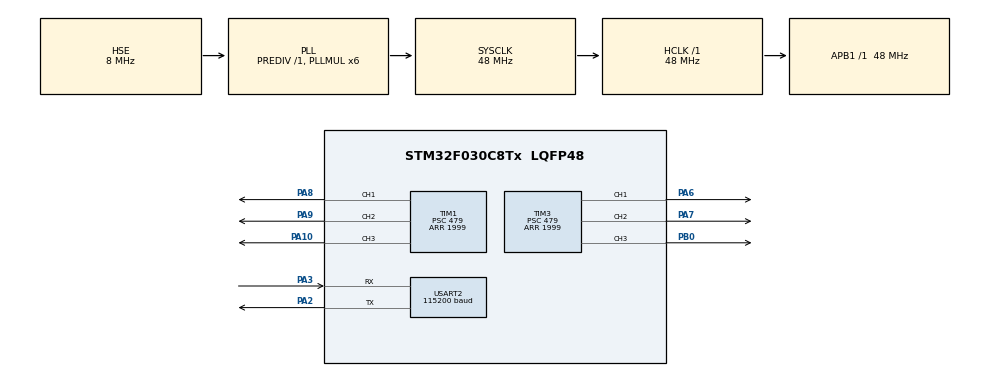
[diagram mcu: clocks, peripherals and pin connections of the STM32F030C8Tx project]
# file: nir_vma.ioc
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Dma.Request0=USART2_RX
Dma.Request1=USART2_TX
Dma.USART2_RX.0.Direction=DMA_PERIPH_TO_MEMORY
Dma.USART2_RX.0.Instance=DMA1_Channel5
Dma.USART2_RX.0.MemDataAlignment=DMA_MDATAALIGN_BYTE
Dma.USART2_RX.0.MemInc=DMA_MINC_ENABLE
Dma.USART2_RX.0.Mode=DMA_CIRCULAR
Dma.USART2_RX.0.PeriphDataAlignment=DMA_PDATAALIGN_BYTE
Dma.USART2_RX.0.PeriphInc=DMA_PINC_DISABLE
Dma.USART2_RX.0.Priority=DMA_PRIORITY_LOW
Dma.USART2_TX.1.Direction=DMA_MEMORY_TO_PERIPH
Dma.USART2_TX.1.Instance=DMA1_Channel4
Dma.USART2_TX.1.MemDataAlignment=DMA_MDATAALIGN_BYTE
Dma.USART2_TX.1.MemInc=DMA_MINC_ENABLE
Dma.USART2_TX.1.Mode=DMA_NORMAL
Dma.USART2_TX.1.PeriphDataAlignment=DMA_PDATAALIGN_BYTE
Dma.USART2_TX.1.PeriphInc=DMA_PINC_DISABLE
Dma.USART2_TX.1.Priority=DMA_PRIORITY_LOW
Mcu.Family=STM32F0
Mcu.Name=STM32F030C8Tx
Mcu.Package=LQFP48
NVIC.DMA1_Channel4_5_IRQn=true\:0\:0\:false\:false\:true\:false\:true\:true
NVIC.USART2_IRQn=true\:0\:0\:false\:false\:true\:true\:true\:true
PA10.Signal=S_TIM1_CH3
PA13.Mode=Serial_Wire
PA13.Signal=SYS_SWDIO
PA14.Mode=Serial_Wire
PA14.Signal=SYS_SWCLK
PA2.Mode=Asynchronous
PA2.Signal=USART2_TX
PA3.Mode=Asynchronous
PA3.Signal=USART2_RX
PA6.Signal=S_TIM3_CH1
PA7.Signal=S_TIM3_CH2
PA8.Signal=S_TIM1_CH1
PA9.Signal=S_TIM1_CH2
PB0.Signal=S_TIM3_CH3
PF0-OSC_IN.Mode=HSE-External-Oscillator
PF0-OSC_IN.Signal=RCC_OSC_IN
PF1-OSC_OUT.Mode=HSE-External-Oscillator
PF1-OSC_OUT.Signal=RCC_OSC_OUT
ProjectManager.HeapSize=0x200
ProjectManager.StackSize=0x400
ProjectManager.TargetToolchain=STM32CubeIDE
RCC.AHBFreq_Value=48000000
RCC.APB1Freq_Value=48000000
RCC.APB1TimFreq_Value=48000000
RCC.HCLKFreq_Value=48000000
RCC.PLLMUL=RCC_PLL_MUL6
RCC.PLLSourceVirtual=RCC_PLLSOURCE_HSE
RCC.SYSCLKFreq_VALUE=48000000
RCC.SYSCLKSource=RCC_SYSCLKSOURCE_PLLCLK
SH.S_TIM1_CH1.0=TIM1_CH1,PWM Generation1 CH1
SH.S_TIM1_CH2.0=TIM1_CH2,PWM Generation2 CH2
SH.S_TIM1_CH3.0=TIM1_CH3,PWM Generation3 CH3
SH.S_TIM3_CH1.0=TIM3_CH1,PWM Generation1 CH1
SH.S_TIM3_CH2.0=TIM3_CH2,PWM Generation2 CH2
SH.S_TIM3_CH3.0=TIM3_CH3,PWM Generation3 CH3
TIM1.Channel-PWM\ Generation1\ CH1=TIM_CHANNEL_1
TIM1.Channel-PWM\ Generation2\ CH2=TIM_CHANNEL_2
TIM1.Channel-PWM\ Generation3\ CH3=TIM_CHANNEL_3
TIM1.Period=1999
TIM1.Prescaler=479
TIM1.Pulse-PWM\ Generation1\ CH1=150
TIM1.Pulse-PWM\ Generation2\ CH2=150
TIM3.Channel-PWM\ Generation1\ CH1=TIM_CHANNEL_1
TIM3.Channel-PWM\ Generation2\ CH2=TIM_CHANNEL_2
TIM3.Channel-PWM\ Generation3\ CH3=TIM_CHANNEL_3
TIM3.Period=1999
TIM3.Prescaler=479
TIM3.Pulse-PWM\ Generation2\ CH2=150
TIM3.Pulse-PWM\ Generation3\ CH3=150
USART2.BaudRate=115200
USART2.Mode=MODE_TX_RX
USART2.Parity=PARITY_NONE
USART2.VirtualMode-Asynchronous=VM_ASYNC
board=custom

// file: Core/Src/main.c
/* USER CODE BEGIN Header */
/**
  ******************************************************************************
  * @file           : main.c
  * @brief          : Main program body
  ******************************************************************************
  * @attention
  *
  * Copyright (c) 2023 STMicroelectronics.
  * All rights reserved.
  *
  * This software is licensed under terms that can be found in the LICENSE file
  * in the root directory of this software component.
  * If no LICENSE file comes with this software, it is provided AS-IS.
  *
  ******************************************************************************
  */
/* USER CODE END Header */
#include "main.h"
#include "dma.h"
#include "tim.h"
#include "usart.h"
#include "gpio.h"

/* USER CODE BEGIN Includes */
#include "Thruster.h"
#include "byteProtocol.h"
/* USER CODE END Includes */

/* USER CODE BEGIN PV */

uint8_t data[6] = {150,150,150,150,150,150}; //ВМА

/* USER CODE END PV */

void SystemClock_Config(void);

/* USER CODE BEGIN 0 */

void ByteProtocol_enter(uint8_t motor_idx,uint8_t rpm) {
    if (motor_idx < 6) {
    	data[motor_idx] = rpm;

    }
}
/* USER CODE END 0 */

int main(void)
{

  /* MCU Configuration--------------------------------------------------------*/

  /* Reset of all peripherals, Initializes the Flash interface and the Systick. */
  HAL_Init();

  /* Configure the system clock */
  SystemClock_Config();

  /* Initialize all configured peripherals */
  MX_GPIO_Init();
  MX_DMA_Init();
  MX_TIM1_Init();
  MX_TIM3_Init();
  MX_USART2_UART_Init();
  /* USER CODE BEGIN 2 */
  ByteProtocol_Init();
  Thruster_Init();

  /* USER CODE END 2 */

  /* Infinite loop */
  while (1)
  {

    /* USER CODE BEGIN 3 */

	 Thruster_Set_Speed(data);

  }
  /* USER CODE END 3 */
}

void SystemClock_Config(void)
{
  RCC_OscInitTypeDef RCC_OscInitStruct = {0};
  RCC_ClkInitTypeDef RCC_ClkInitStruct = {0};

  /** Initializes the RCC Oscillators according to the specified parameters
  * in the RCC_OscInitTypeDef structure.
  */
  RCC_OscInitStruct.OscillatorType = RCC_OSCILLATORTYPE_HSE;
  RCC_OscInitStruct.HSEState = RCC_HSE_ON;
  RCC_OscInitStruct.PLL.PLLState = RCC_PLL_ON;
  RCC_OscInitStruct.PLL.PLLSource = RCC_PLLSOURCE_HSE;
  RCC_OscInitStruct.PLL.PLLMUL = RCC_PLL_MUL6;
  RCC_OscInitStruct.PLL.PREDIV = RCC_PREDIV_DIV1;
  if (HAL_RCC_OscConfig(&RCC_OscInitStruct) != HAL_OK)
  {
    Error_Handler();
  }

  /** Initializes the CPU, AHB and APB buses clocks
  */
  RCC_ClkInitStruct.ClockType = RCC_CLOCKTYPE_HCLK|RCC_CLOCKTYPE_SYSCLK
                              |RCC_CLOCKTYPE_PCLK1;
  RCC_ClkInitStruct.SYSCLKSource = RCC_SYSCLKSOURCE_PLLCLK;
  RCC_ClkInitStruct.AHBCLKDivider = RCC_SYSCLK_DIV1;
  RCC_ClkInitStruct.APB1CLKDivider = RCC_HCLK_DIV1;

  if (HAL_RCC_ClockConfig(&RCC_ClkInitStruct, FLASH_LATENCY_1) != HAL_OK)
  {
    Error_Handler();
  }
}

void Error_Handler(void)
{
  __disable_irq();
  while (1)
  {
  }
}
